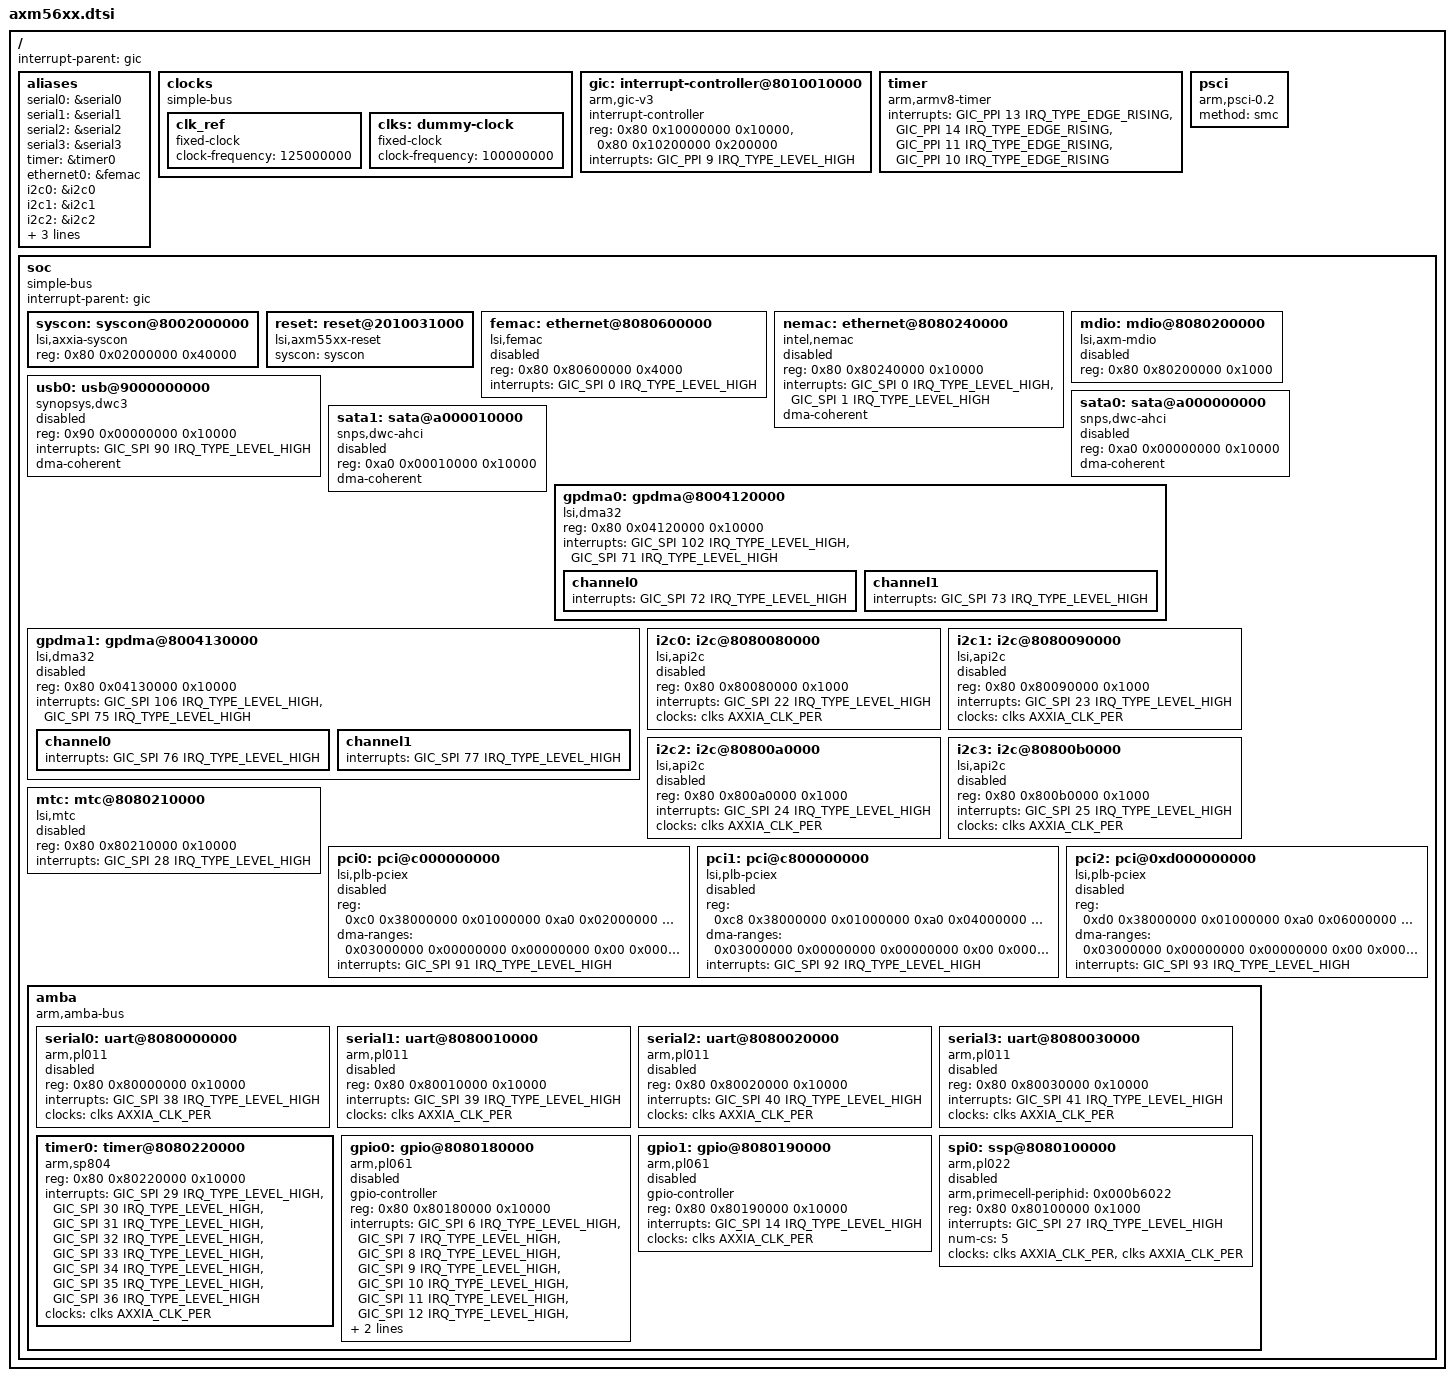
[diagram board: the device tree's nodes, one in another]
/*
 * arch/arm64/boot/dts/intel/axm56xx.dtsi
 *
 * Copyright (C) 2014 Avago Technologies
 *
 * This program is free software; you can redistribute it and/or modify
 * it under the terms of the GNU General Public License as published by
 * the Free Software Foundation; either version 2 of the License, or
 * (at your option) any later version.
 */

#include <dt-bindings/interrupt-controller/arm-gic.h>
#include <dt-bindings/clock/lsi,axm5516-clks.h>

#include "skeleton.dtsi"

/ {
	interrupt-parent = <&gic>;

	aliases {
		serial0	  = &serial0;
		serial1   = &serial1;
		serial2	  = &serial2;
		serial3	  = &serial3;
		timer	  = &timer0;
		ethernet0 = &femac;
		i2c0	  = &i2c0;
		i2c1	  = &i2c1;
		i2c2	  = &i2c2;
		i2c3	  = &i2c3;
		gpdma0	  = &gpdma0;
		gpdma1	  = &gpdma1;
	};

	clocks {
		compatible = "simple-bus";
		#address-cells = <2>;
		#size-cells = <1>;
		ranges;

		clk_ref {
			compatible = "fixed-clock";
			#clock-cells = <0>;
			clock-frequency = <125000000>;
		};

		clks: dummy-clock {
			compatible = "fixed-clock";
			#clock-cells = <1>;
			clock-frequency = <100000000>;
		};
	};

	gic: interrupt-controller@8010010000 {
		compatible = "arm,gic-v3";
		#interrupt-cells = <3>;
		#address-cells = <0>;
		interrupt-controller;
		reg = <0x80 0x10000000 0x10000>,
		      <0x80 0x10200000 0x200000>;
		interrupts = <GIC_PPI 9 IRQ_TYPE_LEVEL_HIGH>;
	};

	timer {
		compatible = "arm,armv8-timer";
		interrupts = <GIC_PPI 13 IRQ_TYPE_EDGE_RISING>,
			     <GIC_PPI 14 IRQ_TYPE_EDGE_RISING>,
			     <GIC_PPI 11 IRQ_TYPE_EDGE_RISING>,
			     <GIC_PPI 10 IRQ_TYPE_EDGE_RISING>;
	};

	psci {
		compatible      = "arm,psci-0.2";
		method          = "smc";
	};

	soc {
		compatible = "simple-bus";
		device_type = "soc";
		#address-cells = <2>;
		#size-cells = <1>;
		interrupt-parent = <&gic>;
		ranges;

		syscon: syscon@8002000000 {
			compatible = "lsi,axxia-syscon", "syscon";
			reg = <0x80 0x02000000 0x40000>;
		};

		reset: reset@2010031000 {
			compatible = "lsi,axm55xx-reset";
			syscon = <&syscon>;
		};


		femac: ethernet@8080600000 {
			compatible = "lsi,femac";
			reg = <0x80 0x80600000 0x4000>;
			interrupts = <GIC_SPI 0 IRQ_TYPE_LEVEL_HIGH>;
			status = "disabled";
		};

		nemac: ethernet@8080240000 {
			compatible = "intel,nemac";
			reg = <0x80 0x80240000 0x10000>;
			interrupts = <GIC_SPI 0 IRQ_TYPE_LEVEL_HIGH>,
				     <GIC_SPI 1 IRQ_TYPE_LEVEL_HIGH>;
			dma-coherent;
			status = "disabled";
		};

		mdio: mdio@8080200000 {
			compatible = "lsi,axm-mdio";
			#address-cells = <1>;
			#size-cells = <0>;
			reg = <0x80 0x80200000 0x1000>;
			status = "disabled";
		};

		usb0: usb@9000000000 {
			compatible = "synopsys,dwc3";
			reg = <0x90 0x00000000 0x10000>;
			interrupts = <GIC_SPI 90 IRQ_TYPE_LEVEL_HIGH>;
			dma-coherent;
			status = "disabled";
		};

		sata0: sata@a000000000 {
			compatible = "snps,dwc-ahci";
			reg = <0xa0 0x00000000 0x10000>;
			dma-coherent;
			status = "disabled";
		};

		sata1: sata@a000010000 {
			compatible = "snps,dwc-ahci";
			reg = <0xa0 0x00010000 0x10000>;
			dma-coherent;
			status = "disabled";
		};

		gpdma0: gpdma@8004120000 {
			compatible = "lsi,dma32";
			reg = <0x80 0x04120000 0x10000>;
			interrupts = <GIC_SPI 102 IRQ_TYPE_LEVEL_HIGH>,
					<GIC_SPI 71 IRQ_TYPE_LEVEL_HIGH>;
			channel0 {
				interrupts = <GIC_SPI 72 IRQ_TYPE_LEVEL_HIGH>;
			};

			channel1 {
				interrupts = <GIC_SPI 73 IRQ_TYPE_LEVEL_HIGH>;
			};
		};

		gpdma1: gpdma@8004130000 {
			compatible = "lsi,dma32";
			reg = <0x80 0x04130000 0x10000>;
			interrupts = <GIC_SPI 106 IRQ_TYPE_LEVEL_HIGH>,
					<GIC_SPI 75 IRQ_TYPE_LEVEL_HIGH>;
			status = "disabled";
			channel0 {
				interrupts = <GIC_SPI 76 IRQ_TYPE_LEVEL_HIGH>;
			};

			channel1 {
				interrupts = <GIC_SPI 77 IRQ_TYPE_LEVEL_HIGH>;
			};
		};

		i2c0: i2c@8080080000 {
			compatible = "lsi,api2c";
			#address-cells = <1>;
			#size-cells = <0>;
			reg = <0x80 0x80080000 0x1000>;
			interrupts = <GIC_SPI 22 IRQ_TYPE_LEVEL_HIGH>;
			clocks = <&clks AXXIA_CLK_PER>;
			clock-names = "i2c";
			status = "disabled";
		};

		i2c1: i2c@8080090000 {
			compatible = "lsi,api2c";
			#address-cells = <1>;
			#size-cells = <0>;
			reg = <0x80 0x80090000 0x1000>;
			interrupts = <GIC_SPI 23 IRQ_TYPE_LEVEL_HIGH>;
			clocks = <&clks AXXIA_CLK_PER>;
			clock-names = "i2c";
			status = "disabled";
		};

		i2c2: i2c@80800a0000 {
			compatible = "lsi,api2c";
			#address-cells = <1>;
			#size-cells = <0>;
			reg = <0x80 0x800a0000 0x1000>;
			interrupts = <GIC_SPI 24 IRQ_TYPE_LEVEL_HIGH>;
			clocks = <&clks AXXIA_CLK_PER>;
			clock-names = "i2c";
			status = "disabled";
		};

		i2c3: i2c@80800b0000 {
			compatible = "lsi,api2c";
			#address-cells = <1>;
			#size-cells = <0>;
			reg = <0x80 0x800b0000 0x1000>;
			interrupts = <GIC_SPI 25 IRQ_TYPE_LEVEL_HIGH>;
			clocks = <&clks AXXIA_CLK_PER>;
			clock-names = "i2c";
			status = "disabled";
		};

		mtc: mtc@8080210000 {
			compatible = "lsi,mtc";
			reg = <0x80 0x80210000 0x10000>;
			interrupts = <GIC_SPI 28 IRQ_TYPE_LEVEL_HIGH>;
			status = "disabled";
		};

		pci0: pci@c000000000 {
			compatible = "lsi,plb-pciex";
			device_type = "pci";
			#interrupt-cells = <1>;
			#size-cells = <2>;
			#address-cells = <3>;
			reg = < 0xc0 0x38000000 0x01000000
				0xa0 0x02000000 0x00008000 >;
			/* Outbound ranges */
			/* < <3-cell PCI addr> <2-cell CPU (PLB) addr>
			<2-cell size> >*/
			ranges = <0x03000000 0x00000000 0x80000000
				0xc0 0x00000000
				0x00 0x20000000>;
			/* Inbound ranges */
			/* < <3-cell PCI addr> <2-cell CPU addr>
			<2-cell size> > */
			dma-ranges = <0x03000000 0x00000000 0x00000000
				0x00 0x00000000
				0x00 0x40000000>;
			interrupts = <GIC_SPI 91 IRQ_TYPE_LEVEL_HIGH>;
			status = "disabled";
		};

		pci1: pci@c800000000 {
			compatible = "lsi,plb-pciex";
			device_type = "pci";
			#interrupt-cells = <1>;
			#size-cells = <2>;
			#address-cells = <3>;
			reg = < 0xc8 0x38000000 0x01000000
				0xa0 0x04000000 0x00008000 >;
			/* Outbound ranges */
			/* < <3-cell PCI addr> <2-cell CPU (PLB) addr>
			<2-cell size> >*/
			ranges = <0x03000000 0x00000000 0xa0000000
				  0xc8 0x00000000
				  0x00 0x20000000>;
			/* Inbound ranges */
			/* < <3-cell PCI addr> <2-cell CPU addr>
			<2-cell size> > */
			dma-ranges = <0x03000000 0x00000000 0x00000000
				      0x00 0x00000000
				      0x00 0x40000000>;
			interrupts = <GIC_SPI 92 IRQ_TYPE_LEVEL_HIGH>;
			status = "disabled";
		};

		pci2: pci@0xd000000000 {
			compatible = "lsi,plb-pciex";
			device_type = "pci";
			#interrupt-cells = <1>;
			#size-cells = <2>;
			#address-cells = <3>;
			reg = < 0xd0 0x38000000 0x01000000
				0xa0 0x06000000 0x00008000 >;
			/* Outbound ranges */
			/* < <3-cell PCI addr> <2-cell CPU (PLB) addr>
			<2-cell size> >*/
			ranges = <0x03000000 0x00000000 0xc0000000
				  0xd0 0x00000000
				  0x00 0x20000000>;
			/* Inbound ranges */
			/* < <3-cell PCI addr> <2-cell CPU addr>
			<2-cell size> > */
			dma-ranges = <0x03000000 0x00000000 0x00000000
				      0x00 0x00000000
				      0x00 0x40000000>;
			interrupts = <GIC_SPI 93 IRQ_TYPE_LEVEL_HIGH>;
			status = "disabled";
		};

		amba {
			compatible = "arm,amba-bus";
			#address-cells = <2>;
			#size-cells = <1>;
			ranges;

			serial0: uart@8080000000 {
				compatible = "arm,pl011", "arm,primecell";
				reg = <0x80 0x80000000 0x10000>;
				interrupts = <GIC_SPI 38 IRQ_TYPE_LEVEL_HIGH>;
				clocks = <&clks AXXIA_CLK_PER>;
				clock-names = "apb_pclk";
				status = "disabled";
			};

			serial1: uart@8080010000 {
				compatible = "arm,pl011", "arm,primecell";
				reg = <0x80 0x80010000 0x10000>;
				interrupts = <GIC_SPI 39 IRQ_TYPE_LEVEL_HIGH>;
				clocks = <&clks AXXIA_CLK_PER>;
				clock-names = "apb_pclk";
				status = "disabled";
			};

			serial2: uart@8080020000 {
				compatible = "arm,pl011", "arm,primecell";
				reg = <0x80 0x80020000 0x10000>;
				interrupts = <GIC_SPI 40 IRQ_TYPE_LEVEL_HIGH>;
				clocks = <&clks AXXIA_CLK_PER>;
				clock-names = "apb_pclk";
				status = "disabled";
			};

			serial3: uart@8080030000 {
				compatible = "arm,pl011", "arm,primecell";
				reg = <0x80 0x80030000 0x10000>;
				interrupts = <GIC_SPI 41 IRQ_TYPE_LEVEL_HIGH>;
				clocks = <&clks AXXIA_CLK_PER>;
				clock-names = "apb_pclk";
				status = "disabled";
			};

			timer0: timer@8080220000 {
				compatible = "arm,sp804", "arm,primecell";
				reg = <0x80 0x80220000 0x10000>;
				interrupts = <GIC_SPI 29 IRQ_TYPE_LEVEL_HIGH>,
					     <GIC_SPI 30 IRQ_TYPE_LEVEL_HIGH>,
					     <GIC_SPI 31 IRQ_TYPE_LEVEL_HIGH>,
					     <GIC_SPI 32 IRQ_TYPE_LEVEL_HIGH>,
					     <GIC_SPI 33 IRQ_TYPE_LEVEL_HIGH>,
					     <GIC_SPI 34 IRQ_TYPE_LEVEL_HIGH>,
					     <GIC_SPI 35 IRQ_TYPE_LEVEL_HIGH>,
					     <GIC_SPI 36 IRQ_TYPE_LEVEL_HIGH>;
				clocks = <&clks AXXIA_CLK_PER>;
				clock-names = "apb_pclk";
			};

			gpio0: gpio@8080180000 {
				#gpio-cells = <2>;
				compatible = "arm,pl061", "arm,primecell";
				gpio-controller;
				reg = <0x80 0x80180000 0x10000>;
				interrupts = <GIC_SPI  6 IRQ_TYPE_LEVEL_HIGH>,
					     <GIC_SPI  7 IRQ_TYPE_LEVEL_HIGH>,
					     <GIC_SPI  8 IRQ_TYPE_LEVEL_HIGH>,
					     <GIC_SPI  9 IRQ_TYPE_LEVEL_HIGH>,
					     <GIC_SPI 10 IRQ_TYPE_LEVEL_HIGH>,
					     <GIC_SPI 11 IRQ_TYPE_LEVEL_HIGH>,
					     <GIC_SPI 12 IRQ_TYPE_LEVEL_HIGH>,
					     <GIC_SPI 13 IRQ_TYPE_LEVEL_HIGH>;
				clocks = <&clks AXXIA_CLK_PER>;
				clock-names = "apb_pclk";
				status = "disabled";
			};

			gpio1: gpio@8080190000 {
				#gpio-cells = <2>;
				compatible = "arm,pl061", "arm,primecell";
				gpio-controller;
				reg = <0x80 0x80190000 0x10000>;
				interrupts = <GIC_SPI 14 IRQ_TYPE_LEVEL_HIGH>;
				clocks = <&clks AXXIA_CLK_PER>;
				clock-names = "apb_pclk";
				status = "disabled";
			};

			spi0: ssp@8080100000 {
				compatible = "arm,pl022", "arm,primecell";
				arm,primecell-periphid = <0x000b6022>;
				#address-cells = <1>;
				#size-cells = <0>;
				reg = <0x80 0x80100000 0x1000>;
				interrupts = <GIC_SPI 27 IRQ_TYPE_LEVEL_HIGH>;
				num-cs = <5>;
				clocks = <&clks AXXIA_CLK_PER>, <&clks AXXIA_CLK_PER>;
				clock-names = "spi", "apb_pclk";
				status = "disabled";
			};
		};
	};
};

/*
  Local Variables:
  mode: C
  End:
*/
